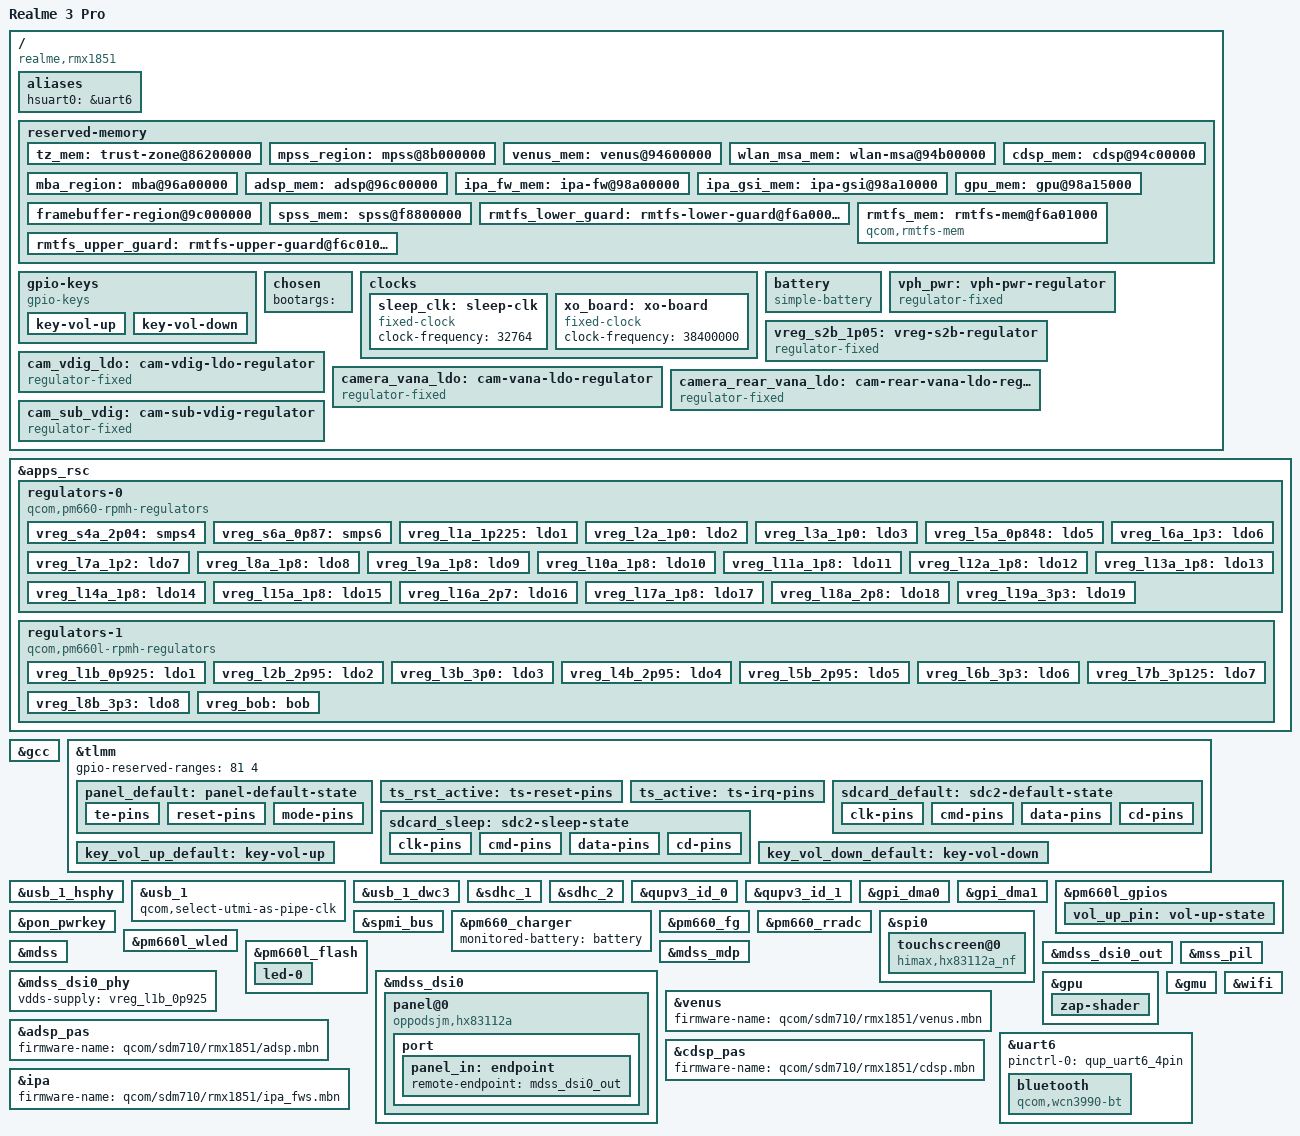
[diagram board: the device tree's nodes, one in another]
// SPDX-License-Identifier: GPL-2.0-only
/*
 * Device tree for Realme 3 Pro
 * Copyright (c) 2025, Yahia Shamaa <yehiashamaa987@gmail.com>
 */

/dts-v1/;

#include <dt-bindings/interrupt-controller/irq.h>
#include <dt-bindings/firmware/qcom,scm.h>
#include <dt-bindings/gpio/gpio.h>
#include <dt-bindings/input/input.h>
#include <dt-bindings/leds/common.h>
#include <dt-bindings/pinctrl/qcom,pmic-gpio.h>
#include <dt-bindings/power/qcom-rpmpd.h>
#include <dt-bindings/sound/qcom,q6afe.h>
#include <dt-bindings/sound/qcom,q6asm.h>
#include <dt-bindings/sound/qcom,q6voice.h>
#include "sdm710.dtsi"
#include "pm660.dtsi"
#include "pm660l.dtsi"

/delete-node/ &mpss_region;
/delete-node/ &venus_mem;
/delete-node/ &wlan_msa_mem;
/delete-node/ &cdsp_mem;
/delete-node/ &mba_region;
/delete-node/ &adsp_mem;
/delete-node/ &ipa_fw_mem;
/delete-node/ &ipa_gsi_mem;
/delete-node/ &gpu_mem;
/delete-node/ &rmtfs_mem;
/delete-node/ &spss_mem;
/delete-node/ &tz_mem;

/ {
	model = "Realme 3 Pro";
	compatible = "realme,rmx1851", "qcom,sdm670";

	qcom,msm-id =	<360 0x0>,
					<393 0x0>;
	qcom,board-id = <8 0>;

	aliases { 
		hsuart0 = &uart6;
	};	
	
	reserved-memory {
		#address-cells = <2>;
		#size-cells = <2>;
		
		tz_mem: trust-zone@86200000 {
			reg = <0 0x86200000 0 0x4900000>;
			no-map;
		};

		mpss_region: mpss@8b000000 {
			reg = <0 0x8b000000 0 0x9600000>;
			no-map;
		};

		venus_mem: venus@94600000 {
			reg = <0 0x94600000 0 0x500000>;
			no-map;
		};

		wlan_msa_mem: wlan-msa@94b00000 {
			reg = <0 0x94b00000 0 0x100000>;
			no-map;
		};

		cdsp_mem: cdsp@94c00000  {
			reg = <0 0x94c00000  0 0x1e00000>;
			no-map;
		};

		mba_region: mba@96a00000 {
			reg = <0 0x96a00000 0 0x200000>;
			no-map;
		};

		adsp_mem: adsp@96c00000  {
			reg = <0 0x96c00000 0 0x1e00000>;
			no-map;
		};

		ipa_fw_mem: ipa-fw@98a00000 {
			reg = <0 0x98a00000 0 0x10000>;
			no-map;
		};

		ipa_gsi_mem: ipa-gsi@98a10000 {
			reg = <0 0x98a10000 0 0x5000>;
			no-map;
		};

		gpu_mem: gpu@98a15000 {
			reg = <0 0x98a15000 0 0x2000>;
			no-map;
		};

		framebuffer-region@9c000000 {
			reg = <0 0x9c000000 0 0x2300000>;
			no-map;
		};

		spss_mem: spss@f8800000 {
			reg = <0 0xf8800000 0 0x800000>;
			no-map;
		};

		rmtfs_lower_guard: rmtfs-lower-guard@f6a00000 {
			reg = <0 0xf6a00000 0 0x1000>;
			no-map;
		};

		rmtfs_mem: rmtfs-mem@f6a01000 {
			compatible = "qcom,rmtfs-mem";
			reg = <0 0xf6a01000 0 0x200000>;
			no-map;

			qcom,client-id = <1>;
			qcom,vmid = <QCOM_SCM_VMID_MSS_MSA>;
		};

		rmtfs_upper_guard: rmtfs-upper-guard@f6c01000 {
			reg = <0 0xf6c01000 0 0x1000>;
			no-map;
		};

	};

	gpio-keys {
		compatible = "gpio-keys";
		autorepeat;

		pinctrl-names = "default";
		pinctrl-0 = <&key_vol_up_default &key_vol_down_default>;

		key-vol-up {
			label = "Volume Up";
			linux,code = <KEY_VOLUMEUP>;
			gpios = <&tlmm 24 GPIO_ACTIVE_LOW>;
		};

		key-vol-down {
			label = "Volume Down";
			linux,code = <KEY_VOLUMEDOWN>;
			gpios = <&tlmm 92 GPIO_ACTIVE_LOW>;
		};
		
	};

	chosen {
		
		bootargs = "";		

		#address-cells = <2>;
		#size-cells = <2>;
		ranges;

		// stdout-path = "framebuffer0";

		// framebuffer0: framebuffer@9c000000 {
		// 	compatible = "simple-framebuffer";
		// 	reg = <0 0x9c000000 0 (1080 * 2340 * 4)>;
		// 	width = <1080>;
		// 	height = <2340>;
		// 	stride = <(1080 * 4)>;
		// 	format = "a8r8g8b8";
		// 	status = "okay";
		// };
	
	};
	
	clocks {
		sleep_clk: sleep-clk {
				compatible = "fixed-clock";
				#clock-cells = <0>;
				clock-frequency = <32764>;
		};

		xo_board: xo-board {
				compatible = "fixed-clock";
				#clock-cells = <0>;
				clock-frequency = <38400000>;
		};
    };

	battery: battery {
		compatible = "simple-battery";
		voltage-min-design-microvolt = <3400000>;
		voltage-max-design-microvolt = <4350000>;
	};

	vph_pwr: vph-pwr-regulator {
		compatible = "regulator-fixed";
		regulator-name = "vph_pwr";
		regulator-min-microvolt = <3312000>;
		regulator-max-microvolt = <3312000>;

		regulator-always-on;
		regulator-boot-on;
	};

	vreg_s2b_1p05: vreg-s2b-regulator {
        compatible = "regulator-fixed";
        regulator-name = "vreg_s2b";
        regulator-min-microvolt = <1050000>;
        regulator-max-microvolt = <1050000>;
    };

	cam_vdig_ldo: cam-vdig-ldo-regulator {
		compatible = "regulator-fixed";
		regulator-name = "camera_vdig_ldo";

		regulator-min-microvolt = <1352000>;
		regulator-max-microvolt = <1352000>;
		regulator-enable-ramp-delay = <135>;

		enable-active-high;
		gpio = <&tlmm 41 0>;

		vin-supply = <&vreg_l6a_1p3>;
	};

	camera_vana_ldo: cam-vana-ldo-regulator {
		compatible = "regulator-fixed";
		regulator-name = "camera_vana_ldo";

		regulator-min-microvolt = <2850000>;
		regulator-max-microvolt = <2850000>;
		regulator-enable-ramp-delay = <233>;

		enable-active-high;
		gpio = <&tlmm 42 0>;

		vin-supply = <&vreg_l6a_1p3>;
	};

	camera_rear_vana_ldo: cam-rear-vana-ldo-regulator {
		compatible = "regulator-fixed";
		regulator-name = "camera_rear_vana_ldo";
		
		regulator-min-microvolt = <2850000>;
		regulator-max-microvolt = <2850000>;
		regulator-enable-ramp-delay = <233>;
		
		enable-active-high;
		gpio = <&tlmm 29 0>;
		
		vin-supply = <&vreg_bob>;
	};

	cam_sub_vdig: cam-sub-vdig-regulator {
		compatible = "regulator-fixed";
		regulator-name = "cam_sub_vdig";
		
		regulator-min-microvolt = <1352000>;
		regulator-max-microvolt = <1352000>;
		regulator-enable-ramp-delay = <233>;
		
		enable-active-high;
		gpio = <&tlmm 43 0>;
		
		vin-supply = <&vreg_l6a_1p3>;
	};
};

&apps_rsc {
	regulators-0 {
		compatible = "qcom,pm660-rpmh-regulators";
		qcom,pmic-id = "a";

		vdd-s1-supply = <&vph_pwr>;
		vdd-s2-supply = <&vph_pwr>;
		vdd-s3-supply = <&vph_pwr>;
		vdd-s4-supply = <&vph_pwr>;
		vdd-s5-supply = <&vph_pwr>;
		vdd-s6-supply = <&vph_pwr>;

		vdd-l1-l6-l7-supply = <&vreg_s6a_0p87>;
		vdd-l2-l3-supply = <&vreg_s2b_1p05>;
		vdd-l5-supply = <&vreg_s2b_1p05>;
		vdd-l8-l9-l10-l11-l12-l13-l14-supply = <&vreg_s4a_2p04>;
		vdd-l15-l16-l17-l18-l19-supply = <&vreg_bob>;

		/*
		 * S1A (FTAPC0), S2A (FTAPC1), S3A (HFAPC1) are managed
		 * by the Core Power Reduction hardened (CPRh) and the
		 * Operating State Manager (OSM) HW automatically.
		 */

		vreg_s4a_2p04: smps4 {
			regulator-min-microvolt = <1808000>;
			regulator-max-microvolt = <2040000>;
			regulator-enable-ramp-delay = <200>;
		};

		vreg_s6a_0p87: smps6 {
			regulator-min-microvolt = <1224000>;
			regulator-max-microvolt = <1352000>;
			regulator-enable-ramp-delay = <150>;
		};

		/* LDOs */
		vreg_l1a_1p225: ldo1 {
			regulator-min-microvolt = <1200000>;
			regulator-max-microvolt = <1250000>;
			regulator-enable-ramp-delay = <250>;
		};

		vreg_l2a_1p0: ldo2 {
			regulator-min-microvolt = <1000000>;
			regulator-max-microvolt = <1000000>;
			regulator-enable-ramp-delay = <250>;
		};

		vreg_l3a_1p0: ldo3 {
			regulator-min-microvolt = <1000000>;
			regulator-max-microvolt = <1000000>;
			regulator-enable-ramp-delay = <250>;
		};

		vreg_l5a_0p848: ldo5 {
			regulator-min-microvolt = <800000>;
			regulator-max-microvolt = <800000>;
			regulator-enable-ramp-delay = <250>;
		};

		vreg_l6a_1p3: ldo6 {
			regulator-min-microvolt = <1248000>;
			regulator-max-microvolt = <1304000>;
			regulator-enable-ramp-delay = <250>;
		};

		vreg_l7a_1p2: ldo7 {
			regulator-min-microvolt = <1200000>;
			regulator-max-microvolt = <1200000>;
			regulator-enable-ramp-delay = <250>;
		};

		vreg_l8a_1p8: ldo8 {
			regulator-min-microvolt = <1800000>;
			regulator-max-microvolt = <1800000>;
			regulator-enable-ramp-delay = <250>;
			regulator-always-on;
		};

		vreg_l9a_1p8: ldo9 {
			regulator-min-microvolt = <1800000>;
			regulator-max-microvolt = <1800000>;
			regulator-enable-ramp-delay = <250>;
		};

		vreg_l10a_1p8: ldo10 {
			regulator-min-microvolt = <1800000>;
			regulator-max-microvolt = <1800000>;
			regulator-enable-ramp-delay = <250>;
		};

		vreg_l11a_1p8: ldo11 {
			regulator-min-microvolt = <1800000>;
			regulator-max-microvolt = <1800000>;
			regulator-enable-ramp-delay = <250>;
		};

		vreg_l12a_1p8: ldo12 {
			regulator-min-microvolt = <1800000>;
			regulator-max-microvolt = <1800000>;
			regulator-enable-ramp-delay = <250>;
		};

		vreg_l13a_1p8: ldo13 {
			regulator-min-microvolt = <1800000>;
			regulator-max-microvolt = <1800000>;
			regulator-enable-ramp-delay = <250>;
		};

		vreg_l14a_1p8: ldo14 {
			regulator-min-microvolt = <1800000>;
			regulator-max-microvolt = <1800000>;
			regulator-enable-ramp-delay = <250>;
		};

		vreg_l15a_1p8: ldo15 {
			regulator-min-microvolt = <1800000>;
			regulator-max-microvolt = <2950000>;
			regulator-enable-ramp-delay = <250>;
		};

		// changed
		vreg_l16a_2p7: ldo16 {
			regulator-min-microvolt = <2696000>;
			regulator-max-microvolt = <2696000>;
			regulator-enable-ramp-delay = <250>;
		};

		vreg_l17a_1p8: ldo17 {
			regulator-min-microvolt = <1800000>;
			regulator-max-microvolt = <2950000>;
			regulator-enable-ramp-delay = <250>;
		};

		vreg_l18a_2p8: ldo18 {
			regulator-min-microvolt = <2600000>;
            regulator-max-microvolt = <2800000>;
			regulator-enable-ramp-delay = <250>;
			regulator-boot-on;
            regulator-always-on;
		};

		vreg_l19a_3p3: ldo19 {
			regulator-min-microvolt = <3000000>;
			regulator-max-microvolt = <3312000>;
			regulator-enable-ramp-delay = <250>;
		};
	};

	regulators-1 {
		compatible = "qcom,pm660l-rpmh-regulators";
		qcom,pmic-id = "b";

		vdd-s1-supply = <&vph_pwr>;
		vdd-s2-supply = <&vph_pwr>;
		vdd-s3-s4-supply = <&vph_pwr>;
		vdd-s5-supply = <&vph_pwr>;

		vdd-l1-l9-l10-supply = <&vreg_s2b_1p05>;
		vdd-l2-supply = <&vreg_bob>;
		vdd-l3-l5-l7-l8-supply = <&vreg_bob>;
		vdd-l4-l6-supply = <&vreg_bob>;
		vdd-bob-supply = <&vph_pwr>;

		/* LDOs */
		vreg_l1b_0p925: ldo1 {
			regulator-min-microvolt = <880000>;
			regulator-max-microvolt = <900000>;
			regulator-enable-ramp-delay = <250>;
		};

		vreg_l2b_2p95: ldo2 {
			regulator-min-microvolt = <1800000>;
			regulator-max-microvolt = <2960000>;
			regulator-enable-ramp-delay = <250>;
		};

		vreg_l3b_3p0: ldo3 {
			regulator-min-microvolt = <2850000>;
			regulator-max-microvolt = <3008000>;
			regulator-enable-ramp-delay = <250>;
		};

		vreg_l4b_2p95: ldo4 {
			regulator-min-microvolt = <2960000>;
			regulator-max-microvolt = <2960000>;
			regulator-enable-ramp-delay = <250>;
		};

		vreg_l5b_2p95: ldo5 {
			regulator-min-microvolt = <2960000>;
			regulator-max-microvolt = <2960000>;
			regulator-enable-ramp-delay = <250>;
		};

		vreg_l6b_3p3: ldo6 {
			regulator-min-microvolt = <3008000>;
			regulator-max-microvolt = <3300000>;
			regulator-enable-ramp-delay = <250>;
		};

		vreg_l7b_3p125: ldo7 {
			regulator-min-microvolt = <3088000>;
			regulator-max-microvolt = <3100000>;
			regulator-enable-ramp-delay = <250>;
		};

		vreg_l8b_3p3: ldo8 {
			regulator-min-microvolt = <3300000>;
			regulator-max-microvolt = <3312000>;
			regulator-enable-ramp-delay = <250>;
		};

		/*
		 * Downstream specifies a fixed voltage of 3.312 V, but the
		 * PMIC4 BOB ranges don't support that. Widen the range a
		 * little to avoid adding a new BOB regulator type.
		 */
		vreg_bob: bob {
			regulator-min-microvolt = <3296000>;
			regulator-max-microvolt = <3328000>;
			regulator-enable-ramp-delay = <500>;
		};
	};
};

&gcc {
	protected-clocks = <GCC_QSPI_CORE_CLK>,
			   <GCC_QSPI_CORE_CLK_SRC>,
			   <GCC_QSPI_CNOC_PERIPH_AHB_CLK>;
};

&tlmm {

	gpio-reserved-ranges = <81 4>;

	panel_default: panel-default-state {
		te-pins {
			pins = "gpio10";
			function = "mdp_vsync";
			drive-strength = <2>;
			bias-pull-down;
		};

		reset-pins {
			pins = "gpio26";
			function = "gpio";
			drive-strength = <8>;
			bias-disable;
		};

		mode-pins {
			pins = "gpio4";
			function = "gpio";
			drive-strength = <8>;
			bias-disable;
		};
	};

	ts_rst_active: ts-reset-pins {
		pins = "gpio99";
    	function = "gpio";

		drive-strength = <8>; 
		bias-pull-up;
		output-high;
	};

	ts_active: ts-irq-pins {
		pins = "gpio125";
		function = "gpio";

		drive-strength = <8>;
		bias-disable;
	};

	sdcard_default: sdc2-default-state {
		clk-pins {
			pins = "sdc2_clk";
			drive-strength = <16>;
			bias-disable;
		};

		cmd-pins {
			pins = "sdc2_cmd";
			drive-strength = <10>;
			bias-pull-up;
		};

		data-pins {
			pins = "sdc2_data";
			drive-strength = <10>;
			bias-pull-up;
		};

		cd-pins {
			pins = "gpio96";
			function = "gpio";
			drive-strength = <2>;
			bias-pull-up;
		};
	};

	sdcard_sleep: sdc2-sleep-state {
		clk-pins {
			pins = "sdc2_clk";
			drive-strength = <2>;
			bias-disable;
		};

		cmd-pins {
			pins = "sdc2_cmd";
			drive-strength = <2>;
			bias-pull-up;
		};

		data-pins {
			pins = "sdc2_data";
			drive-strength = <2>;
			bias-pull-up;
		};

		cd-pins {
			pins = "gpio96";
			function = "gpio";
			drive-strength = <2>;
			bias-disable;
		};
	};

	key_vol_up_default: key-vol-up {
        pins = "gpio24";
        function = "gpio";
        drive-strength = <2>;
        bias-disable;
        input-enable;
    };

	key_vol_down_default: key-vol-down {
        pins = "gpio92";
        function = "gpio";
        drive-strength = <2>;
        bias-disable;
        input-enable;
    };

};

&usb_1_hsphy {
	vdd-supply = <&vreg_l1b_0p925>;
	vdda-pll-supply = <&vreg_l10a_1p8>;
	vdda-phy-dpdm-supply = <&vreg_l7b_3p125>;

	status = "okay";
};

&usb_1 {
	qcom,select-utmi-as-pipe-clk;
	status = "okay";
};

&usb_1_dwc3 {
	/* Only peripheral works for now */
	dr_mode = "peripheral";

	/* Do not assume that sdm670.dtsi will never support USB 3.0 */
	phys = <&usb_1_hsphy>;
	phy-names = "usb2-phy";
	maximum-speed = "high-speed";
};

&sdhc_1 {
	supports-cqe;
	mmc-hs200-1_8v;
	mmc-hs400-1_8v;
	mmc-ddr-1_8v;

	qcom,ddr-config = <0xc3040873>;

	vmmc-supply = <&vreg_l4b_2p95>;
	vqmmc-supply = <&vreg_l8a_1p8>;

	status = "okay";
};

&sdhc_2 {
	status = "okay";

	vmmc-supply = <&vreg_l5b_2p95>;
	vqmmc-supply = <&vreg_l2b_2p95>;

	cd-gpios = <&tlmm 96 GPIO_ACTIVE_HIGH>;

	pinctrl-0 = <&sdcard_default>;
	pinctrl-names = "default";

	no-sdio;
	no-mmc;
};


&qupv3_id_0 {
	status = "okay";
};

&qupv3_id_1 {
	status = "okay";
};

&gpi_dma0 {
	status = "okay";
};

&gpi_dma1 {
	status = "okay";
};

&pm660l_gpios {
	vol_up_pin: vol-up-state {
		pins = "gpio24";
		function = "gpio";
		qcom,drive-strength = <PMIC_GPIO_STRENGTH_NO>;
		input-enable;
		bias-pull-up;
	};
};


&pon_pwrkey {
	status = "okay";
};


&spmi_bus {
	status = "okay";
};

&pm660_charger {
	monitored-battery = <&battery>;
	status = "okay";
};

&pm660_fg {
	monitored-battery = <&battery>;
	power-supplies = <&pm660_charger>;
	status = "okay";
};


/* Haptics are incredibly weak, not noticeable so is disabled */

// &pm660_haptics {
// 	status = "okay";
// };

&pm660_rradc {
	status = "okay";
};

&spi0 {
	status = "okay";
	#address-cells = <1>;
    #size-cells = <0>;

	touchscreen@0 {
        status = "okay";
        reg = <0>;
        compatible = "himax,hx83112a_nf";

        chip-name = "OPPO_TP_NOFLASH";
        spi-max-frequency = <9600000>;
        interrupt-parent = <&tlmm>;
		
		interrupts = <125 0x01>;
        reset-gpios = <&tlmm 99 0x00>;
        irq-gpios = <&tlmm 125 0x2001>;
        lcd-reset-gpio = <&tlmm 26 0x00>;
         
		pinctrl-names = "default";
        pinctrl-0 = <&ts_active &ts_rst_active>;

		touchpanel,max-num-support = <10>;
        touchpanel,tx-rx-num = <16 36>;
        touchpanel,panel-coords = <1080 2340>;
        touchpanel,display-coords = <1080 2340>;

        incell_screen;
        irq_need_dev_resume_ok;
        fw_edge_limit_support;
        black_gesture_support;
        charger_pump_support;
        headset_pump_support;        
		esd_handle_support;
        black_gesture_test_support;
        game_switch_support;
        noflash_support;
        lcd_trigger_load_tp_fw_support;
        smart_gesture_support;
        pressure_report_support;
        fw_update_app_support;

        touchpanel,button-type = <4>;
    };
};

&pm660l_wled {
	qcom,switching-freq = <800>;
	qcom,current-limit-microamp = <20000>;
	qcom,num-strings = <2>;

	status = "okay";
};

&pm660l_flash {
	status = "okay";

	led-0 {
		function = LED_FUNCTION_FLASH;
		color = <LED_COLOR_ID_WHITE>;
		led-sources = <1>, <2>;
		led-max-microamp = <350000>;
		flash-max-microamp = <1000000>;
		flash-max-timeout-us = <1280000>;
	};
};

&mdss {
    status = "okay";
};

&mdss_mdp {
    status = "okay";
};

&mdss_dsi0 {
	vdda-supply = <&vreg_l1a_1p225>;
	status = "okay";

	pinctrl-names = "default";
	pinctrl-0 = <&panel_default>;

	power-supply = <&vreg_l6b_3p3>;

	panel@0 {
		compatible = "oppodsjm,hx83112a";

		reg = <0>;

		backlight = <&pm660l_wled>;
		reset-gpios = <&tlmm 26 GPIO_ACTIVE_LOW>;

		port {
			panel_in: endpoint {
				remote-endpoint = <&mdss_dsi0_out>;
			};
		};
	};
};

&mdss_dsi0_out {
	data-lanes = <0 1 2 3>;
	remote-endpoint = <&panel_in>;
};

&mdss_dsi0_phy {
    vdds-supply = <&vreg_l1b_0p925>;
    status = "okay";
};

&venus {
	status = "okay";
	firmware-name = "qcom/sdm710/rmx1851/venus.mbn";
};

&adsp_pas {
	status = "okay";
	firmware-name = "qcom/sdm710/rmx1851/adsp.mbn";
};

&cdsp_pas {
	status = "okay";
	
	firmware-name = "qcom/sdm710/rmx1851/cdsp.mbn";
};

&mss_pil {
	status = "okay";
	firmware-name = "qcom/sdm710/rmx1851/mba.mbn", "qcom/sdm710/rmx1851/modem.mbn";
};


&ipa {
	firmware-name = "qcom/sdm710/rmx1851/ipa_fws.mbn";
	status = "okay";
};

&gpu {
	status = "okay";
	
	zap-shader {
		memory-region = <&gpu_mem>;
		firmware-name = "qcom/sdm710/rmx1851/a615_zap.mbn";
	};
};

&gmu {
	status = "okay";
};

&uart6 {
	pinctrl-0 = <&qup_uart6_4pin>;
	status = "okay";

	bluetooth {
		compatible = "qcom,wcn3990-bt";
		vddio-supply = <&vph_pwr>;
		vddxo-supply = <&vreg_l9a_1p8>;
		vddrf-supply = <&vreg_l6a_1p3>;
		vddch0-supply = <&vreg_l19a_3p3>;
		max-speed = <3200000>;
	};
};

/* Doesn't work */

&wifi {
	vdd-0.8-cx-mx-supply = <&vreg_l5a_0p848>;
	vdd-1.8-xo-supply = <&vreg_l9a_1p8>;
	vdd-1.3-rfa-supply = <&vreg_l6a_1p3>;
	vdd-3.3-ch0-supply = <&vreg_l19a_3p3>;

	qcom,snoc-host-cap-8bit-quirk;

	status = "okay";
};


// Cameras don't have drivers:

/* Front and main bus */
// &cci_i2c1 {
// 
// };
